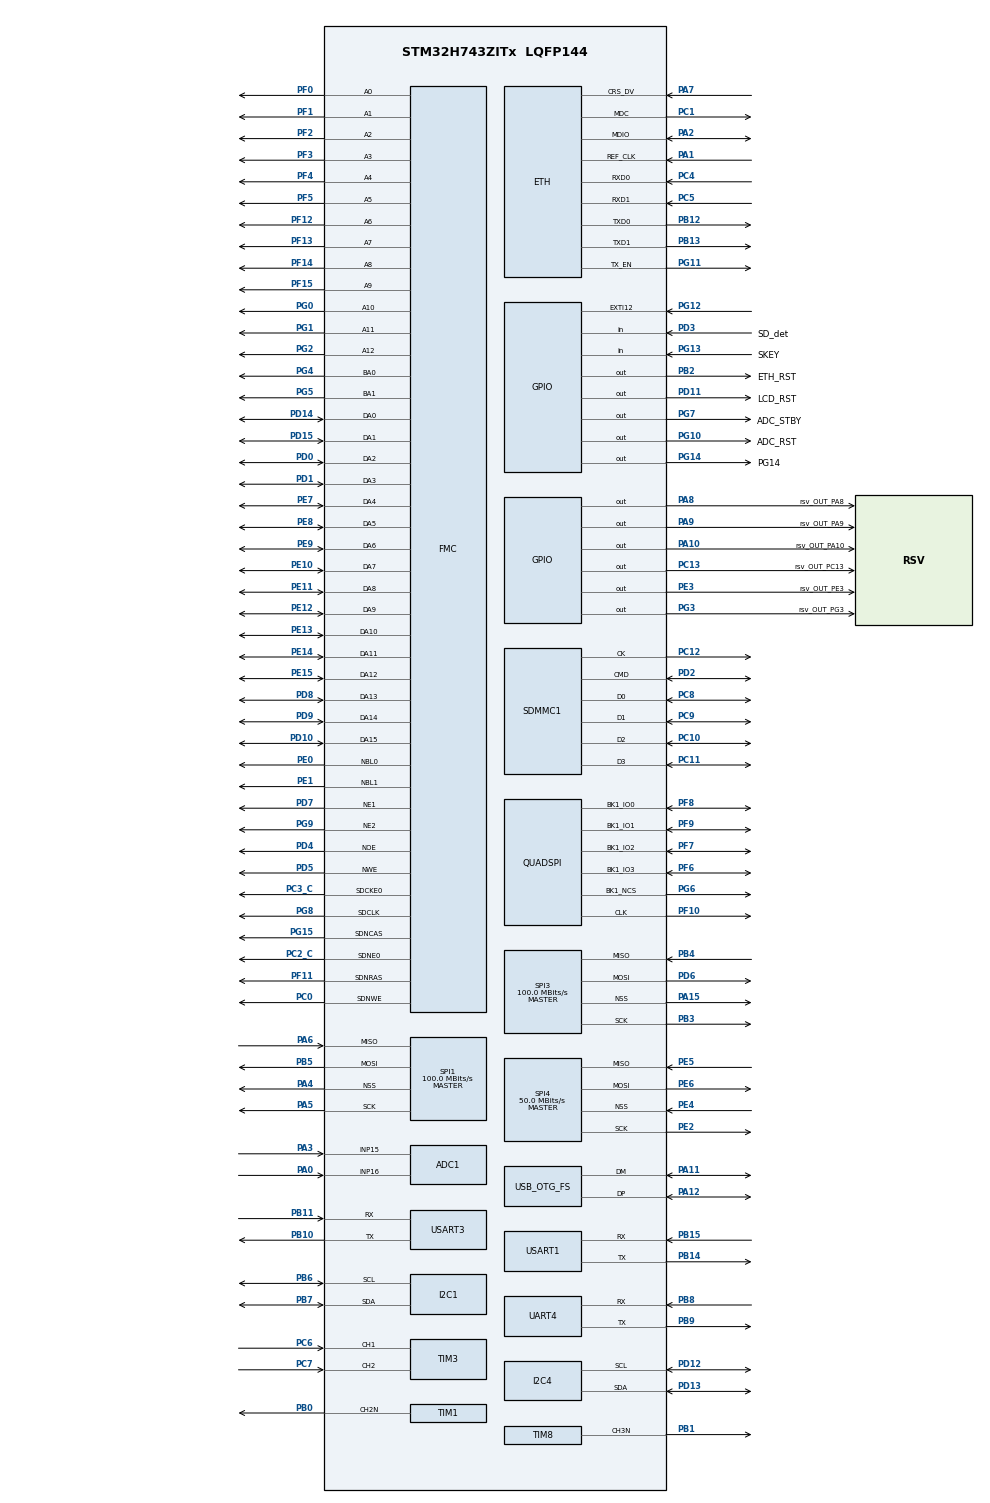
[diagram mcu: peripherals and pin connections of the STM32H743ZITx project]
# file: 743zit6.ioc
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ADC1.Channel-0\#ChannelRegularConversion=ADC_CHANNEL_15
ADC1.NbrOfConversionFlag=1
ADC1.OffsetNumber-0\#ChannelRegularConversion=ADC_OFFSET_NONE
ADC1.OffsetSignedSaturation-0\#ChannelRegularConversion=DISABLE
ADC1.Rank-0\#ChannelRegularConversion=1
ADC1.SamplingTime-0\#ChannelRegularConversion=ADC_SAMPLETIME_1CYCLE_5
ADC1.master=1
CORTEX_M7.AccessPermission-Cortex_Memory_Protection_Unit_Region0_Settings=MPU_REGION_FULL_ACCESS
CORTEX_M7.AccessPermission-Cortex_Memory_Protection_Unit_Region1_Settings=MPU_REGION_FULL_ACCESS
CORTEX_M7.AccessPermission-Cortex_Memory_Protection_Unit_Region2_Settings=MPU_REGION_FULL_ACCESS
CORTEX_M7.AccessPermission-Cortex_Memory_Protection_Unit_Region3_Settings=MPU_REGION_FULL_ACCESS
CORTEX_M7.BaseAddress-Cortex_Memory_Protection_Unit_Region0_Settings=0x30040000
CORTEX_M7.BaseAddress-Cortex_Memory_Protection_Unit_Region1_Settings=0x30044000
CORTEX_M7.BaseAddress-Cortex_Memory_Protection_Unit_Region2_Settings=0x64000000
CORTEX_M7.BaseAddress-Cortex_Memory_Protection_Unit_Region3_Settings=0xC0000000
CORTEX_M7.CPU_DCache=Enabled
CORTEX_M7.CPU_ICache=Enabled
CORTEX_M7.Enable-Cortex_Memory_Protection_Unit_Region0_Settings=MPU_REGION_ENABLE
CORTEX_M7.Enable-Cortex_Memory_Protection_Unit_Region1_Settings=MPU_REGION_ENABLE
CORTEX_M7.Enable-Cortex_Memory_Protection_Unit_Region2_Settings=MPU_REGION_ENABLE
CORTEX_M7.Enable-Cortex_Memory_Protection_Unit_Region3_Settings=MPU_REGION_ENABLE
CORTEX_M7.IsBufferable-Cortex_Memory_Protection_Unit_Region0_Settings=MPU_ACCESS_BUFFERABLE
CORTEX_M7.IsBufferable-Cortex_Memory_Protection_Unit_Region2_Settings=MPU_ACCESS_BUFFERABLE
CORTEX_M7.IsBufferable-Cortex_Memory_Protection_Unit_Region3_Settings=MPU_ACCESS_BUFFERABLE
CORTEX_M7.IsCacheable-Cortex_Memory_Protection_Unit_Region1_Settings=MPU_ACCESS_CACHEABLE
CORTEX_M7.IsCacheable-Cortex_Memory_Protection_Unit_Region3_Settings=MPU_ACCESS_CACHEABLE
CORTEX_M7.MPU_Control=MPU_PRIVILEGED_DEFAULT
CORTEX_M7.Size-Cortex_Memory_Protection_Unit_Region0_Settings=MPU_REGION_SIZE_256B
CORTEX_M7.Size-Cortex_Memory_Protection_Unit_Region1_Settings=MPU_REGION_SIZE_16KB
CORTEX_M7.Size-Cortex_Memory_Protection_Unit_Region2_Settings=MPU_REGION_SIZE_256MB
CORTEX_M7.Size-Cortex_Memory_Protection_Unit_Region3_Settings=MPU_REGION_SIZE_32MB
CORTEX_M7.TypeExtField-Cortex_Memory_Protection_Unit_Region3_Settings=MPU_TEX_LEVEL1
ETH.MediaInterface=HAL_ETH_RMII_MODE
FATFS.BSP.number=1
FATFS0.BSP.STBoard=false
FATFS0.BSP.api=Unknown
FATFS0.BSP.instance=PD3
FATFS0.BSP.ip=GPIO
FATFS0.BSP.mode=Input
FATFS0.BSP.name=Detect_SDIO
FATFS0.BSP.solution=PD3
FMC.AddressSetupTime2=0
FMC.BusTurnAroundDuration2=15
FMC.CASLatency1=FMC_SDRAM_CAS_LATENCY_2
FMC.ColumnBitsNumber1=FMC_SDRAM_COLUMN_BITS_NUM_9
FMC.DataSetupTime2=15
FMC.ExitSelfRefreshDelay1=8
FMC.ExtendedMode2=FMC_EXTENDED_MODE_DISABLE
FMC.LoadToActiveDelay1=2
FMC.RCDDelay1=2
FMC.RPDelay1=2
FMC.RPDelay2=2
FMC.ReadBurst1=FMC_SDRAM_RBURST_ENABLE
FMC.ReadBurst2=FMC_SDRAM_RBURST_ENABLE
FMC.RowCycleDelay1=6
FMC.RowCycleDelay2=6
FMC.SDClockPeriod1=FMC_SDRAM_CLOCK_PERIOD_2
FMC.SDClockPeriod2=FMC_SDRAM_CLOCK_PERIOD_2
FMC.SelfRefreshTime1=6
FMC.WriteFifo1=FMC_WRITE_FIFO_ENABLE
FMC.WriteOperation1=FMC_WRITE_OPERATION_ENABLE
FMC.WriteRecoveryTime1=4
FREERTOS.BinarySemaphores01=EVENT_ADC,Dynamic,NULL,Available;EVENT_FFT,Dynamic,NULL,Available;EVENT_LVGL_REFERSH,Dynamic,NULL,Available;EVENT_LVGL_TASK,Dynamic,NULL,Available
FREERTOS.Tasks01=refersh_lvgl,1,1024,Refersh_LVGL,Default,NULL,Dynamic,NULL,NULL;task_FFT,0,1300,TASK_FFT,Default,NULL,Dynamic,NULL,NULL;task_lvgl,0,1300,TASK_LVGL,Default,NULL,Dynamic,NULL,NULL
FREERTOS.configENABLE_FPU=1
FREERTOS.configTOTAL_HEAP_SIZE=64*1024
FREERTOS.configUSE_MALLOC_FAILED_HOOK=1
FREERTOS.configUSE_MUTEXES=1
I2C1.Timing=0x10C0ECFF
I2C4.Timing=0x10C0ECFF
LWIP.BSP.number=1
LWIP.GATEWAY_ADDRESS=059.067.235.129
LWIP.IP_ADDRESS=059.067.235.208
LWIP.LWIP_DHCP=0
LWIP.LWIP_HTTPD=1
LWIP.LWIP_HTTPD_CGI=1
LWIP.LWIP_HTTPD_SSI=1
LWIP.MEM_SIZE=14336
LWIP.NETMASK_ADDRESS=255.255.255.000
LWIP.Version=v2.1.2_Cube
LWIP0.BSP.STBoard=false
LWIP0.BSP.api=BSP_COMPONENT_DRIVER
LWIP0.BSP.component=LAN8742
LWIP0.BSP.instance=LAN8742
LWIP0.BSP.name=Driver_PHY
LWIP0.BSP.solution=LAN8742
Mcu.Family=STM32H7
Mcu.Name=STM32H743ZITx
Mcu.Package=LQFP144
NVIC.ETH_IRQn=true\:5\:0\:false\:false\:false\:true\:true\:true\:true
NVIC.EXTI15_10_IRQn=true\:5\:0\:false\:false\:true\:true\:true\:true\:true
NVIC.PriorityGroup=NVIC_PRIORITYGROUP_4
NVIC.TIM4_IRQn=true\:15\:0\:false\:false\:true\:false\:false\:true\:true
NVIC.TimeBase=TIM4_IRQn
NVIC.TimeBaseIP=TIM4
PA0.Mode=IN16-Single-Ended
PA0.Signal=ADC1_INP16
PA1.GPIO_Speed=GPIO_SPEED_FREQ_VERY_HIGH
PA1.Mode=RMII
PA1.Signal=ETH_REF_CLK
PA10.GPIO_Label=rsv_OUT_PA10
PA10.Signal=GPIO_Output
PA11.GPIO_Speed=GPIO_SPEED_FREQ_VERY_HIGH
PA11.Mode=Device_Only
PA11.Signal=USB_OTG_FS_DM
PA12.GPIO_Speed=GPIO_SPEED_FREQ_VERY_HIGH
PA12.Mode=Device_Only
PA12.Signal=USB_OTG_FS_DP
PA13\ (JTMS/SWDIO).Mode=Serial_Wire
PA13\ (JTMS/SWDIO).Signal=DEBUG_JTMS-SWDIO
PA14\ (JTCK/SWCLK).Mode=Serial_Wire
PA14\ (JTCK/SWCLK).Signal=DEBUG_JTCK-SWCLK
PA15\ (JTDI).Mode=NSS_Signal_Hard_Output
PA15\ (JTDI).Signal=SPI3_NSS
PA2.GPIO_Speed=GPIO_SPEED_FREQ_VERY_HIGH
PA2.Mode=RMII
PA2.Signal=ETH_MDIO
PA3.Signal=ADCx_INP15
PA4.Mode=NSS_Signal_Hard_Output
PA4.Signal=SPI1_NSS
PA5.Mode=Full_Duplex_Master
PA5.Signal=SPI1_SCK
PA6.Mode=Full_Duplex_Master
PA6.Signal=SPI1_MISO
PA7.GPIO_Speed=GPIO_SPEED_FREQ_VERY_HIGH
PA7.Mode=RMII
PA7.Signal=ETH_CRS_DV
PA8.GPIO_Label=rsv_OUT_PA8
PA8.Signal=GPIO_Output
PA9.GPIO_Label=rsv_OUT_PA9
PA9.Signal=GPIO_Output
PB0.Mode=PWM Generation2 CH2N
PB0.Signal=TIM1_CH2N
PB1.Mode=PWM Generation3 CH3N
PB1.Signal=TIM8_CH3N
PB10.Mode=Asynchronous
PB10.Signal=USART3_TX
PB11.Mode=Asynchronous
PB11.Signal=USART3_RX
PB12.GPIO_Speed=GPIO_SPEED_FREQ_VERY_HIGH
PB12.Mode=RMII
PB12.Signal=ETH_TXD0
PB13.GPIO_Speed=GPIO_SPEED_FREQ_VERY_HIGH
PB13.Mode=RMII
PB13.Signal=ETH_TXD1
PB14.Mode=Asynchronous
PB14.Signal=USART1_TX
PB15.Mode=Asynchronous
PB15.Signal=USART1_RX
PB2.GPIO_Label=ETH_RST
PB2.Signal=GPIO_Output
PB3\ (JTDO/TRACESWO).Mode=Full_Duplex_Master
PB3\ (JTDO/TRACESWO).Signal=SPI3_SCK
PB4\ (NJTRST).Mode=Full_Duplex_Master
PB4\ (NJTRST).Signal=SPI3_MISO
PB5.Mode=Full_Duplex_Master
PB5.Signal=SPI1_MOSI
PB6.Mode=I2C
PB6.Signal=I2C1_SCL
PB7.Mode=I2C
PB7.Signal=I2C1_SDA
PB8.Mode=Asynchronous
PB8.Signal=UART4_RX
PB9.Mode=Asynchronous
PB9.Signal=UART4_TX
PC0.Signal=FMC_SDNWE
PC1.GPIO_Speed=GPIO_SPEED_FREQ_VERY_HIGH
PC1.Mode=RMII
PC1.Signal=ETH_MDC
PC10.Mode=SD_4_bits_Wide_bus
PC10.Signal=SDMMC1_D2
PC11.Mode=SD_4_bits_Wide_bus
PC11.Signal=SDMMC1_D3
PC12.Mode=SD_4_bits_Wide_bus
PC12.Signal=SDMMC1_CK
PC13.GPIO_Label=rsv_OUT_PC13
PC13.Signal=GPIO_Output
PC14-OSC32_IN\ (OSC32_IN).Mode=LSE-External-Oscillator
PC14-OSC32_IN\ (OSC32_IN).Signal=RCC_OSC32_IN
PC15-OSC32_OUT\ (OSC32_OUT).Mode=LSE-External-Oscillator
PC15-OSC32_OUT\ (OSC32_OUT).Signal=RCC_OSC32_OUT
PC2_C.Mode=SdramChipSelect1_1
PC2_C.Signal=FMC_SDNE0
PC3_C.Mode=SdramChipSelect1_1
PC3_C.Signal=FMC_SDCKE0
PC4.GPIO_Speed=GPIO_SPEED_FREQ_VERY_HIGH
PC4.Mode=RMII
PC4.Signal=ETH_RXD0
PC5.GPIO_Speed=GPIO_SPEED_FREQ_VERY_HIGH
PC5.Mode=RMII
PC5.Signal=ETH_RXD1
PC6.Signal=S_TIM3_CH1
PC7.Signal=S_TIM3_CH2
PC8.Mode=SD_4_bits_Wide_bus
PC8.Signal=SDMMC1_D0
PC9.Mode=SD_4_bits_Wide_bus
PC9.Signal=SDMMC1_D1
PD0.Signal=FMC_D2_DA2
PD1.Signal=FMC_D3_DA3
PD10.Signal=FMC_D15_DA15
PD11.GPIO_Label=LCD_RST
PD11.Signal=GPIO_Output
PD12.Mode=I2C
PD12.Signal=I2C4_SCL
PD13.Mode=I2C
PD13.Signal=I2C4_SDA
PD14.Signal=FMC_D0_DA0
PD15.Signal=FMC_D1_DA1
PD2.Mode=SD_4_bits_Wide_bus
PD2.Signal=SDMMC1_CMD
PD3.GPIO_Label=SD_det
PD3.Signal=GPIO_Input
PD4.Signal=FMC_NOE
PD5.Signal=FMC_NWE
PD6.Mode=Full_Duplex_Master
PD6.Signal=SPI3_MOSI
PD7.Mode=NorPsramChipSelect1_1
PD7.Signal=FMC_NE1
PD8.Signal=FMC_D13_DA13
PD9.Signal=FMC_D14_DA14
PE0.Signal=FMC_NBL0
PE1.Signal=FMC_NBL1
PE10.Signal=FMC_D7_DA7
PE11.Signal=FMC_D8_DA8
PE12.Signal=FMC_D9_DA9
PE13.Signal=FMC_D10_DA10
PE14.Signal=FMC_D11_DA11
PE15.Signal=FMC_D12_DA12
PE2.Mode=Full_Duplex_Master
PE2.Signal=SPI4_SCK
PE3.GPIO_Label=rsv_OUT_PE3
PE3.Signal=GPIO_Output
PE4.Mode=NSS_Signal_Hard_Input
PE4.Signal=SPI4_NSS
PE5.Mode=Full_Duplex_Master
PE5.Signal=SPI4_MISO
PE6.Mode=Full_Duplex_Master
PE6.Signal=SPI4_MOSI
PE7.Signal=FMC_D4_DA4
PE8.Signal=FMC_D5_DA5
PE9.Signal=FMC_D6_DA6
PF0.Signal=FMC_A0
PF1.Signal=FMC_A1
PF10.Mode=Single Bank 1
PF10.Signal=QUADSPI_CLK
PF11.Signal=FMC_SDNRAS
PF12.Signal=FMC_A6
PF13.Signal=FMC_A7
PF14.Signal=FMC_A8
PF15.Signal=FMC_A9
PF2.Signal=FMC_A2
PF3.Signal=FMC_A3
PF4.Signal=FMC_A4
PF5.Signal=FMC_A5
PF6.Mode=Single Bank 1
PF6.Signal=QUADSPI_BK1_IO3
PF7.Mode=Single Bank 1
PF7.Signal=QUADSPI_BK1_IO2
PF8.Mode=Single Bank 1
PF8.Signal=QUADSPI_BK1_IO0
PF9.Mode=Single Bank 1
PF9.Signal=QUADSPI_BK1_IO1
PG0.Signal=FMC_A10
PG1.Signal=FMC_A11
PG10.GPIO_Label=ADC_RST
PG10.Signal=GPIO_Output
PG11.GPIO_Speed=GPIO_SPEED_FREQ_VERY_HIGH
PG11.Mode=RMII
PG11.Signal=ETH_TX_EN
PG12.Signal=GPXTI12
PG13.GPIO_Label=SKEY
PG13.Signal=GPIO_Input
PG14.GPIO_Label=PG14
PG14.Signal=GPIO_Output
PG15.Signal=FMC_SDNCAS
PG2.Signal=FMC_A12
PG3.GPIO_Label=rsv_OUT_PG3
PG3.Signal=GPIO_Output
PG4.Signal=FMC_A14_BA0
PG5.Signal=FMC_A15_BA1
PG6.Mode=Single Bank 1
PG6.Signal=QUADSPI_BK1_NCS
PG7.GPIO_Label=ADC_STBY
PG7.Signal=GPIO_Output
PG8.Signal=FMC_SDCLK
PG9.Mode=NorPsramChipSelect2_2
PG9.Signal=FMC_NE2
PH0-OSC_IN\ (PH0).Mode=HSE-External-Oscillator
PH0-OSC_IN\ (PH0).Signal=RCC_OSC_IN
PH1-OSC_OUT\ (PH1).Mode=HSE-External-Oscillator
PH1-OSC_OUT\ (PH1).Signal=RCC_OSC_OUT
ProjectManager.HeapSize=0x200
ProjectManager.StackSize=0x400
ProjectManager.TargetToolchain=Makefile
RCC.ADCFreq_Value=75000000
RCC.APB1Freq_Value=100000000
RCC.APB2Freq_Value=100000000
RCC.APB3Freq_Value=100000000
RCC.APB4Freq_Value=100000000
RCC.CortexFreq_Value=400000000
RCC.D1PPRE=RCC_APB3_DIV2
RCC.D2PPRE1=RCC_APB1_DIV2
RCC.D2PPRE2=RCC_APB2_DIV2
RCC.D3PPRE=RCC_APB4_DIV2
RCC.DIVM1=1
RCC.DIVM2=1
RCC.DIVN1=97
RCC.DIVN2=18
RCC.DIVQ1=4
RCC.HCLKFreq_Value=200000000
RCC.HPRE=RCC_HCLK_DIV2
RCC.HSE_VALUE=8192000
RCC.PLL2FRACN=2544
RCC.PLL2_VCI_Range-AdvancedSettings=RCC_PLL2VCIRANGE_0
RCC.PLL3_VCO_SEL-AdvancedSettings=RCC_PLL3VCOWIDE
RCC.PLLFRACN=5376
RCC.PLLSourceVirtual=RCC_PLLSOURCE_HSE
RCC.PWR_Regulator_Voltage_Scale=PWR_REGULATOR_VOLTAGE_SCALE0
RCC.RTCClockSelection=RCC_RTCCLKSOURCE_LSE
RCC.SYSCLKFreq_VALUE=400000000
RCC.SYSCLKSource=RCC_SYSCLKSOURCE_PLLCLK
RCC.USBCLockSelection=RCC_USBCLKSOURCE_HSI48
RCC.USBFreq_Value=48000000
RTC.Format=RTC_FORMAT_BIN
SH.ADCx_INP15.0=ADC1_INP15,IN15-Single-Ended
SH.FMC_A0.0=FMC_A0,13b-sda1
SH.FMC_A1.0=FMC_A1,13b-sda1
SH.FMC_A10.0=FMC_A10,13b-sda1
SH.FMC_A11.0=FMC_A11,13b-sda1
SH.FMC_A12.0=FMC_A12,13b-sda1
SH.FMC_A14_BA0.0=FMC_BA0,FourSdramBanks1
SH.FMC_A15_BA1.0=FMC_BA1,FourSdramBanks1
SH.FMC_A2.0=FMC_A2,13b-sda1
SH.FMC_A3.0=FMC_A3,13b-sda1
SH.FMC_A4.0=FMC_A4,13b-sda1
SH.FMC_A5.0=FMC_A5,13b-sda1
SH.FMC_A6.0=FMC_A6,A6_2
SH.FMC_A6.1=FMC_A6,13b-sda1
SH.FMC_A7.0=FMC_A7,13b-sda1
SH.FMC_A8.0=FMC_A8,13b-sda1
SH.FMC_A9.0=FMC_A9,13b-sda1
SH.FMC_D0_DA0.0=FMC_DA0,16b-da1
SH.FMC_D0_DA0.1=FMC_D0,16b-d2
SH.FMC_D0_DA0.2=FMC_D0,sd-16b-d1
SH.FMC_D10_DA10.0=FMC_DA10,16b-da1
SH.FMC_D10_DA10.1=FMC_D10,16b-d2
SH.FMC_D10_DA10.2=FMC_D10,sd-16b-d1
SH.FMC_D11_DA11.0=FMC_DA11,16b-da1
SH.FMC_D11_DA11.1=FMC_D11,16b-d2
SH.FMC_D11_DA11.2=FMC_D11,sd-16b-d1
SH.FMC_D12_DA12.0=FMC_DA12,16b-da1
SH.FMC_D12_DA12.1=FMC_D12,16b-d2
SH.FMC_D12_DA12.2=FMC_D12,sd-16b-d1
SH.FMC_D13_DA13.0=FMC_DA13,16b-da1
SH.FMC_D13_DA13.1=FMC_D13,16b-d2
SH.FMC_D13_DA13.2=FMC_D13,sd-16b-d1
SH.FMC_D14_DA14.0=FMC_DA14,16b-da1
SH.FMC_D14_DA14.1=FMC_D14,16b-d2
SH.FMC_D14_DA14.2=FMC_D14,sd-16b-d1
SH.FMC_D15_DA15.0=FMC_DA15,16b-da1
SH.FMC_D15_DA15.1=FMC_D15,16b-d2
SH.FMC_D15_DA15.2=FMC_D15,sd-16b-d1
SH.FMC_D1_DA1.0=FMC_DA1,16b-da1
SH.FMC_D1_DA1.1=FMC_D1,16b-d2
SH.FMC_D1_DA1.2=FMC_D1,sd-16b-d1
SH.FMC_D2_DA2.0=FMC_DA2,16b-da1
SH.FMC_D2_DA2.1=FMC_D2,16b-d2
SH.FMC_D2_DA2.2=FMC_D2,sd-16b-d1
SH.FMC_D3_DA3.0=FMC_DA3,16b-da1
SH.FMC_D3_DA3.1=FMC_D3,16b-d2
SH.FMC_D3_DA3.2=FMC_D3,sd-16b-d1
SH.FMC_D4_DA4.0=FMC_DA4,16b-da1
SH.FMC_D4_DA4.1=FMC_D4,16b-d2
SH.FMC_D4_DA4.2=FMC_D4,sd-16b-d1
SH.FMC_D5_DA5.0=FMC_DA5,16b-da1
SH.FMC_D5_DA5.1=FMC_D5,16b-d2
SH.FMC_D5_DA5.2=FMC_D5,sd-16b-d1
SH.FMC_D6_DA6.0=FMC_DA6,16b-da1
SH.FMC_D6_DA6.1=FMC_D6,16b-d2
SH.FMC_D6_DA6.2=FMC_D6,sd-16b-d1
SH.FMC_D7_DA7.0=FMC_DA7,16b-da1
SH.FMC_D7_DA7.1=FMC_D7,16b-d2
SH.FMC_D7_DA7.2=FMC_D7,sd-16b-d1
SH.FMC_D8_DA8.0=FMC_DA8,16b-da1
SH.FMC_D8_DA8.1=FMC_D8,16b-d2
SH.FMC_D8_DA8.2=FMC_D8,sd-16b-d1
SH.FMC_D9_DA9.0=FMC_DA9,16b-da1
SH.FMC_D9_DA9.1=FMC_D9,16b-d2
SH.FMC_D9_DA9.2=FMC_D9,sd-16b-d1
SH.FMC_NBL0.0=FMC_NBL0,Sd2ByteEnable1
SH.FMC_NBL1.0=FMC_NBL1,Sd2ByteEnable1
SH.FMC_NOE.0=FMC_NOE,MuxedPsram1
SH.FMC_NOE.1=FMC_NOE,Lcd2
SH.FMC_NWE.0=FMC_NWE,MuxedPsram1
SH.FMC_NWE.1=FMC_NWE,Lcd2
SH.FMC_SDCLK.0=FMC_SDCLK,13b-sda1
SH.FMC_SDNCAS.0=FMC_SDNCAS,13b-sda1
SH.FMC_SDNRAS.0=FMC_SDNRAS,13b-sda1
SH.FMC_SDNWE.0=FMC_SDNWE,13b-sda1
SH.S_TIM3_CH1.0=TIM3_CH1,Encoder_Interface
SH.S_TIM3_CH2.0=TIM3_CH2,Encoder_Interface
SPI1.CalculateBaudRate=100.0 MBits/s
SPI1.Direction=SPI_DIRECTION_2LINES
SPI1.Mode=SPI_MODE_MASTER
SPI1.VirtualNSS=VM_NSSHARD
SPI1.VirtualType=VM_MASTER
SPI3.CalculateBaudRate=100.0 MBits/s
SPI3.Direction=SPI_DIRECTION_2LINES
SPI3.Mode=SPI_MODE_MASTER
SPI3.VirtualNSS=VM_NSSHARD
SPI3.VirtualType=VM_MASTER
SPI4.CalculateBaudRate=50.0 MBits/s
SPI4.Direction=SPI_DIRECTION_2LINES
SPI4.Mode=SPI_MODE_MASTER
SPI4.VirtualNSS=VM_NSSHARD
SPI4.VirtualType=VM_MASTER
TIM1.AutoReloadPreload=TIM_AUTORELOAD_PRELOAD_ENABLE
TIM1.Channel-PWM\ Generation2\ CH2N=TIM_CHANNEL_2
TIM1.Period=1000
TIM1.Prescaler=240-1
TIM1.Pulse-PWM\ Generation2\ CH2N=500
TIM8.AutoReloadPreload=TIM_AUTORELOAD_PRELOAD_ENABLE
TIM8.Channel-PWM\ Generation3\ CH3N=TIM_CHANNEL_3
TIM8.Period=25-1
TIM8.Prescaler=625-1
TIM8.Pulse-PWM\ Generation3\ CH3N=10
USART1.VirtualMode-Asynchronous=VM_ASYNC
USART3.VirtualMode-Asynchronous=VM_ASYNC
USB_OTG_FS.VirtualMode=Device_Only
VP_FATFS_VS_SDIO.Mode=SDIO
VP_FREERTOS_VS_CMSIS_V1.Mode=CMSIS_V1
VP_LWIP_VS_Enabled.Mode=Enabled
VP_RTC_VS_RTC_Activate.Mode=RTC_Enabled
VP_RTC_VS_RTC_Calendar.Mode=RTC_Calendar
VP_SYS_VS_tim4.Mode=TIM4
VP_TIM1_VS_ClockSourceINT.Mode=Internal
VP_TIM8_VS_ClockSourceINT.Mode=Internal
board=custom

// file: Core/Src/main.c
/* USER CODE BEGIN Header */
/**
  ******************************************************************************
  * @file           : main.c
  * @brief          : Main program body
  ******************************************************************************
  * @attention
  *
  * <h2><center>&copy; Copyright (c) 2024 STMicroelectronics.
  * All rights reserved.</center></h2>
  *
  * This software component is licensed by ST under BSD 3-Clause license,
  * the "License"; You may not use this file except in compliance with the
  * License. You may obtain a copy of the License at:
  *                        opensource.org/licenses/BSD-3-Clause
  *
  ******************************************************************************
  */
/* USER CODE END Header */
#include "main.h"
#include "cmsis_os.h"
#include "adc.h"
#include "fatfs.h"
#include "i2c.h"
#include "lwip.h"
#include "quadspi.h"
#include "rtc.h"
#include "sdmmc.h"
#include "spi.h"
#include "tim.h"
#include "usart.h"
#include "usb_otg.h"
#include "gpio.h"
#include "fmc.h"

/* USER CODE BEGIN Includes */
#include "sdmmc.h"
#include "ad7606.h"
#include "lcd.h"
#include "lv_port_indev.h"
#include "lvgl.h"
#include "lv_port_fs.h"
#include "lv_port_disp.h"
#include "fatfs.h"
#include "gui_guider.h"
#include "events_init.h"
#include "sdcard_test.h"
#include "arm_math.h"
#include "dsp_fft.h"
#include "lv_snapshot.h"
#include "lv_bmp.h"
// #include "task_page1.h"
#include "sdram.h"
/* USER CODE END Includes */

/* USER CODE BEGIN PTD */
lv_ui guider_ui;

/* USER CODE END PTD */

/* USER CODE BEGIN PV */
AD7606Dev ad7606dev;
short adcResult;
short adcBuf[testCHs];
uint16_t cnt=0;
uint16_t MyRTC_Time[] = {0, 0, 0, 0, 0, 0};
/* USER CODE END PV */

void SystemClock_Config(void);
static void MPU_Config(void);
void MX_FREERTOS_Init(void);

int main(void)
{

  /* MPU Configuration--------------------------------------------------------*/
  MPU_Config();

  /* Enable I-Cache---------------------------------------------------------*/
  SCB_EnableICache();

  /* Enable D-Cache---------------------------------------------------------*/
  SCB_EnableDCache();

  /* MCU Configuration--------------------------------------------------------*/

  /* Reset of all peripherals, Initializes the Flash interface and the Systick. */
  HAL_Init();

  /* Configure the system clock */
  SystemClock_Config();

  /* Initialize all configured peripherals */
  MX_GPIO_Init();
  MX_RTC_Init();
  MX_TIM1_Init();
  MX_ADC1_Init();
  MX_USB_OTG_FS_PCD_Init();
  MX_TIM3_Init();
  MX_FMC_Init();
  MX_I2C1_Init();
  MX_I2C4_Init();
  MX_QUADSPI_Init();
  MX_SDMMC1_SD_Init();
  MX_SPI1_Init();
  MX_SPI3_Init();
  MX_SPI4_Init();
  MX_TIM8_Init();
  MX_UART4_Init();
  MX_USART1_UART_Init();
  MX_USART3_UART_Init();
  MX_FATFS_Init();
  /* USER CODE BEGIN 2 */

 // HAL_NVIC_DisableIRQ(EXTI15_10_IRQn);
  // HAL_FMC_MspInit();

  lv_init();

  lv_port_disp_init();
  lv_port_indev_init();
  HAL_Delay(10);
  setup_ui(&guider_ui);
  HAL_SD_MspInit(&hsd1);

  HAL_TIM_Base_Start_IT(&htim1);
  ad7606ini(&ad7606dev);
  MX_FATFS_Init();
  //MyRTC_ReadTime();
  HAL_Delay(100);
  FatFs_Check();
  lv_port_fs_init();
  events_init(&guider_ui);

  // HAL_TIMEx_PWMN_Start(&htim1,TIM_CHANNEL_2);
  // ad7606ini(&ad7606dev);
  // HAL_TIMEx_PWMN_Start(&htim8,TIM_CHANNEL_3);

  /* USER CODE END 2 */

  /* Call init function for freertos objects (in freertos.c) */
  MX_FREERTOS_Init();
  /* Start scheduler */
  osKernelStart();

  /* We should never get here as control is now taken by the scheduler */
  /* Infinite loop */
  while (1)
  {

  }
}

void SystemClock_Config(void)
{
  RCC_OscInitTypeDef RCC_OscInitStruct = {0};
  RCC_ClkInitTypeDef RCC_ClkInitStruct = {0};

  /** Supply configuration update enable
  */
  HAL_PWREx_ConfigSupply(PWR_LDO_SUPPLY);
  /** Configure the main internal regulator output voltage
  */
  __HAL_PWR_VOLTAGESCALING_CONFIG(PWR_REGULATOR_VOLTAGE_SCALE0);

  while(!__HAL_PWR_GET_FLAG(PWR_FLAG_VOSRDY)) {}
  /** Configure LSE Drive Capability
  */
  HAL_PWR_EnableBkUpAccess();
  __HAL_RCC_LSEDRIVE_CONFIG(RCC_LSEDRIVE_LOW);
  /** Macro to configure the PLL clock source
  */
  __HAL_RCC_PLL_PLLSOURCE_CONFIG(RCC_PLLSOURCE_HSE);
  /** Initializes the RCC Oscillators according to the specified parameters
  * in the RCC_OscInitTypeDef structure.
  */
  RCC_OscInitStruct.OscillatorType = RCC_OSCILLATORTYPE_HSI48|RCC_OSCILLATORTYPE_HSE
                              |RCC_OSCILLATORTYPE_LSE;
  RCC_OscInitStruct.HSEState = RCC_HSE_ON;
  RCC_OscInitStruct.LSEState = RCC_LSE_ON;
  RCC_OscInitStruct.HSI48State = RCC_HSI48_ON;
  RCC_OscInitStruct.PLL.PLLState = RCC_PLL_ON;
  RCC_OscInitStruct.PLL.PLLSource = RCC_PLLSOURCE_HSE;
  RCC_OscInitStruct.PLL.PLLM = 1;
  RCC_OscInitStruct.PLL.PLLN = 97;
  RCC_OscInitStruct.PLL.PLLP = 2;
  RCC_OscInitStruct.PLL.PLLQ = 4;
  RCC_OscInitStruct.PLL.PLLR = 2;
  RCC_OscInitStruct.PLL.PLLRGE = RCC_PLL1VCIRANGE_3;
  RCC_OscInitStruct.PLL.PLLVCOSEL = RCC_PLL1VCOWIDE;
  RCC_OscInitStruct.PLL.PLLFRACN = 5376;
  if (HAL_RCC_OscConfig(&RCC_OscInitStruct) != HAL_OK)
  {
    Error_Handler();
  }
  /** Initializes the CPU, AHB and APB buses clocks
  */
  RCC_ClkInitStruct.ClockType = RCC_CLOCKTYPE_HCLK|RCC_CLOCKTYPE_SYSCLK
                              |RCC_CLOCKTYPE_PCLK1|RCC_CLOCKTYPE_PCLK2
                              |RCC_CLOCKTYPE_D3PCLK1|RCC_CLOCKTYPE_D1PCLK1;
  RCC_ClkInitStruct.SYSCLKSource = RCC_SYSCLKSOURCE_PLLCLK;
  RCC_ClkInitStruct.SYSCLKDivider = RCC_SYSCLK_DIV1;
  RCC_ClkInitStruct.AHBCLKDivider = RCC_HCLK_DIV2;
  RCC_ClkInitStruct.APB3CLKDivider = RCC_APB3_DIV2;
  RCC_ClkInitStruct.APB1CLKDivider = RCC_APB1_DIV2;
  RCC_ClkInitStruct.APB2CLKDivider = RCC_APB2_DIV2;
  RCC_ClkInitStruct.APB4CLKDivider = RCC_APB4_DIV2;

  if (HAL_RCC_ClockConfig(&RCC_ClkInitStruct, FLASH_LATENCY_2) != HAL_OK)
  {
    Error_Handler();
  }
}

/* MPU Configuration */

void MPU_Config(void)
{
  MPU_Region_InitTypeDef MPU_InitStruct = {0};

  /* Disables the MPU */
  HAL_MPU_Disable();
  /** Initializes and configures the Region and the memory to be protected
  */
  MPU_InitStruct.Enable = MPU_REGION_ENABLE;
  MPU_InitStruct.Number = MPU_REGION_NUMBER0;
  MPU_InitStruct.BaseAddress = 0x30040000;
  MPU_InitStruct.Size = MPU_REGION_SIZE_256B;
  MPU_InitStruct.SubRegionDisable = 0x0;
  MPU_InitStruct.TypeExtField = MPU_TEX_LEVEL0;
  MPU_InitStruct.AccessPermission = MPU_REGION_FULL_ACCESS;
  MPU_InitStruct.DisableExec = MPU_INSTRUCTION_ACCESS_ENABLE;
  MPU_InitStruct.IsShareable = MPU_ACCESS_NOT_SHAREABLE;
  MPU_InitStruct.IsCacheable = MPU_ACCESS_NOT_CACHEABLE;
  MPU_InitStruct.IsBufferable = MPU_ACCESS_BUFFERABLE;

  HAL_MPU_ConfigRegion(&MPU_InitStruct);
  /** Initializes and configures the Region and the memory to be protected
  */
  MPU_InitStruct.Number = MPU_REGION_NUMBER1;
  MPU_InitStruct.BaseAddress = 0x30044000;
  MPU_InitStruct.Size = MPU_REGION_SIZE_16KB;
  MPU_InitStruct.IsCacheable = MPU_ACCESS_CACHEABLE;
  MPU_InitStruct.IsBufferable = MPU_ACCESS_NOT_BUFFERABLE;

  HAL_MPU_ConfigRegion(&MPU_InitStruct);
  /** Initializes and configures the Region and the memory to be protected
  */
  MPU_InitStruct.Number = MPU_REGION_NUMBER2;
  MPU_InitStruct.BaseAddress = 0x64000000;
  MPU_InitStruct.Size = MPU_REGION_SIZE_256MB;
  MPU_InitStruct.IsCacheable = MPU_ACCESS_NOT_CACHEABLE;
  MPU_InitStruct.IsBufferable = MPU_ACCESS_BUFFERABLE;

  HAL_MPU_ConfigRegion(&MPU_InitStruct);
  /** Initializes and configures the Region and the memory to be protected
  */
  MPU_InitStruct.Number = MPU_REGION_NUMBER3;
  MPU_InitStruct.BaseAddress = 0xC0000000;
  MPU_InitStruct.Size = MPU_REGION_SIZE_32MB;
  MPU_InitStruct.TypeExtField = MPU_TEX_LEVEL1;
  MPU_InitStruct.IsCacheable = MPU_ACCESS_CACHEABLE;

  HAL_MPU_ConfigRegion(&MPU_InitStruct);
  /* Enables the MPU */
  HAL_MPU_Enable(MPU_PRIVILEGED_DEFAULT);

}

void HAL_TIM_PeriodElapsedCallback(TIM_HandleTypeDef *htim)
{
  /* USER CODE BEGIN Callback 0 */
  static uint16_t temp = 0;
  static uint16_t counter = 0;

  /* USER CODE END Callback 0 */
  if (htim->Instance == TIM4) {
    HAL_IncTick();
  }
  /* USER CODE BEGIN Callback 1 */
  if (htim->Instance == TIM4)
  {
    temp++;
    counter++;
    if (temp == 5)
    {
      lv_tick_inc(5);
      temp = 0;
    }
  }

  /* USER CODE END Callback 1 */
}

void Error_Handler(void)
{
  __disable_irq();
  while (1)
  {
  }
}

/************************ (C) COPYRIGHT STMicroelectronics *****END OF FILE****/

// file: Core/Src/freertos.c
/* USER CODE BEGIN Header */
/**
 ******************************************************************************
 * File Name          : freertos.c
 * Description        : Code for freertos applications
 ******************************************************************************
 * @attention
 *
 * <h2><center>&copy; Copyright (c) 2024 STMicroelectronics.
 * All rights reserved.</center></h2>
 *
 * This software component is licensed by ST under Ultimate Liberty license
 * SLA0044, the "License"; You may not use this file except in compliance with
 * the License. You may obtain a copy of the License at:
 *                             www.st.com/SLA0044
 *
 ******************************************************************************
 */
/* USER CODE END Header */

#include "FreeRTOS.h"
#include "task.h"
#include "main.h"
#include "cmsis_os.h"

/* USER CODE BEGIN Includes */
#include "lwip/apps/httpd.h"
#include "ad7606.h"
#include "lcd.h"
#include "gui_guider.h"
#include "arm_math.h"
#include "tim.h"
#include "dsp_fft.h"
#include "lvgl.h"
#include "lv_chart.h"
#include "task.h"
#include "task_page1.h"
#include "gpio.h"
#include "sdmmc.h"
#include "events_init.h"
/* USER CODE END Includes */

/* USER CODE BEGIN PTD */
ALIGN_32BYTES(FFT fft_1V)
__attribute__((section(".SDRAM")));

ALIGN_32BYTES(FFT fft_2V)
__attribute__((section(".SDRAM")));
ALIGN_32BYTES(FFT fft_3V)
__attribute__((section(".SDRAM")));
ALIGN_32BYTES(FFT fft_NV)
__attribute__((section(".SDRAM")));

ALIGN_32BYTES(FFT fft_1I)
__attribute__((section(".SDRAM")));
ALIGN_32BYTES(FFT fft_2I)
__attribute__((section(".SDRAM")));
ALIGN_32BYTES(FFT fft_3I)
__attribute__((section(".SDRAM")));
ALIGN_32BYTES(FFT fft_NI)
__attribute__((section(".SDRAM")));

ALIGN_32BYTES(phase P1)
__attribute__((section(".SDRAM")));
ALIGN_32BYTES(phase P2)
__attribute__((section(".SDRAM")));
ALIGN_32BYTES(phase P3)
__attribute__((section(".SDRAM")));
ALIGN_32BYTES(phase PN)
__attribute__((section(".SDRAM")));

ALIGN_32BYTES(Voltage_three Voltage)
__attribute__((section(".SDRAM")));

lv_chart_series_t *ser1;
lv_chart_series_t *ser2;
lv_chart_series_t *ser3;
lv_chart_series_t *serN;

lv_chart_series_t *ser1_I;
lv_chart_series_t *ser2_I;
lv_chart_series_t *ser3_I;
lv_chart_series_t *serN_I;
extern uint8_t V_I_flag;
extern uint8_t L1_flag;
extern uint8_t L2_flag;
extern uint8_t L3_flag;
extern uint8_t LN_flag;
extern uint8_t L1_I_flag;
extern uint8_t L2_I_flag;
extern uint8_t L3_I_flag;
extern uint8_t LN_I_flag;
extern AD7606Dev ad7606dev;
extern SD_HandleTypeDef hsd1;
/* USER CODE END PTD */

osThreadId refersh_lvglHandle;
osThreadId task_FFTHandle;
osThreadId task_lvglHandle;
osSemaphoreId EVENT_ADCHandle;
osSemaphoreId EVENT_FFTHandle;
osSemaphoreId EVENT_LVGL_REFERSHHandle;
osSemaphoreId EVENT_LVGL_TASKHandle;

void Refersh_LVGL(void const *argument);
void TASK_FFT(void const *argument);
void TASK_LVGL(void const *argument);
void init_form_stop();
extern void MX_LWIP_Init(void);
void MX_FREERTOS_Init(void); /* (MISRA C 2004 rule 8.1) */

/* GetIdleTaskMemory prototype (linked to static allocation support) */
void vApplicationGetIdleTaskMemory(StaticTask_t **ppxIdleTaskTCBBuffer, StackType_t **ppxIdleTaskStackBuffer, uint32_t *pulIdleTaskStackSize);

/* Hook prototypes */
void vApplicationMallocFailedHook(void);

/* USER CODE BEGIN 5 */
void vApplicationMallocFailedHook(void)
{
  /* vApplicationMallocFailedHook() will only be called if
  configUSE_MALLOC_FAILED_HOOK is set to 1 in FreeRTOSConfig.h. It is a hook
  function that will get called if a call to pvPortMalloc() fails.
  pvPortMalloc() is called internally by the kernel whenever a task, queue,
  timer or semaphore is created. It is also called by various parts of the
  demo application. If heap_1.c or heap_2.c are used, then the size of the
  heap available to pvPortMalloc() is defined by configTOTAL_HEAP_SIZE in
  FreeRTOSConfig.h, and the xPortGetFreeHeapSize() API function can be used
  to query the size of free heap space that remains (although it does not
  provide information on how the remaining heap might be fragmented). */
  printf("malloc fail\r\n");
  while (1)
  {

    HAL_GPIO_TogglePin(PG14_GPIO_Port, PG14_Pin);
    osDelay(200);
  }
}
/* USER CODE END 5 */

/* USER CODE BEGIN GET_IDLE_TASK_MEMORY */
static StaticTask_t xIdleTaskTCBBuffer;
static StackType_t xIdleStack[configMINIMAL_STACK_SIZE];

void vApplicationGetIdleTaskMemory(StaticTask_t **ppxIdleTaskTCBBuffer, StackType_t **ppxIdleTaskStackBuffer, uint32_t *pulIdleTaskStackSize)
{
  *ppxIdleTaskTCBBuffer = &xIdleTaskTCBBuffer;
  *ppxIdleTaskStackBuffer = &xIdleStack[0];
  *pulIdleTaskStackSize = configMINIMAL_STACK_SIZE;
  /* place for user code */
}
/* USER CODE END GET_IDLE_TASK_MEMORY */

void MX_FREERTOS_Init(void)
{

  /* Create the semaphores(s) */
  /* definition and creation of EVENT_ADC */
  osSemaphoreDef(EVENT_ADC);
  EVENT_ADCHandle = osSemaphoreCreate(osSemaphore(EVENT_ADC), 1);

  /* definition and creation of EVENT_FFT */
  osSemaphoreDef(EVENT_FFT);
  EVENT_FFTHandle = osSemaphoreCreate(osSemaphore(EVENT_FFT), 1);

  /* definition and creation of EVENT_LVGL_REFERSH */
  osSemaphoreDef(EVENT_LVGL_REFERSH);
  EVENT_LVGL_REFERSHHandle = osSemaphoreCreate(osSemaphore(EVENT_LVGL_REFERSH), 1);

  /* definition and creation of EVENT_LVGL_TASK */
  osSemaphoreDef(EVENT_LVGL_TASK);
  EVENT_LVGL_TASKHandle = osSemaphoreCreate(osSemaphore(EVENT_LVGL_TASK), 1);

  /* Create the thread(s) */
  /* definition and creation of refersh_lvgl */
  osThreadDef(refersh_lvgl, Refersh_LVGL, osPriorityAboveNormal, 0, 1024);
  refersh_lvglHandle = osThreadCreate(osThread(refersh_lvgl), NULL);

  /* definition and creation of task_FFT */
  osThreadDef(task_FFT, TASK_FFT, osPriorityNormal, 0, 1300);
  task_FFTHandle = osThreadCreate(osThread(task_FFT), NULL);

  /* definition and creation of task_lvgl */
  osThreadDef(task_lvgl, TASK_LVGL, osPriorityNormal, 0, 1300);
  task_lvglHandle = osThreadCreate(osThread(task_lvgl), NULL);

}

void Refersh_LVGL(void const *argument)
{
  /* init code for LWIP */
  MX_LWIP_Init();
  /* USER CODE BEGIN Refersh_LVGL */
  httpd_init();
  FFT_Init(&fft_1V, SAMPLING, FFT_LENGTH, 1); // 1表示电压
  FFT_Init(&fft_2V, SAMPLING, FFT_LENGTH, 1);
  FFT_Init(&fft_3V, SAMPLING, FFT_LENGTH, 1);
  FFT_Init(&fft_NV, SAMPLING, FFT_LENGTH, 1);

  FFT_Init(&fft_1I, SAMPLING, FFT_LENGTH, 0); // 0表示电流
  FFT_Init(&fft_2I, SAMPLING, FFT_LENGTH, 0);
  FFT_Init(&fft_3I, SAMPLING, FFT_LENGTH, 0);
  FFT_Init(&fft_NI, SAMPLING, FFT_LENGTH, 0);

  PHASE_Init(&P1, &fft_1V, &fft_1I);
  PHASE_Init(&P2, &fft_2V, &fft_2I);
  PHASE_Init(&P3, &fft_3V, &fft_3I);
  PHASE_Init(&PN, &fft_NV, &fft_NI);

  Voltage_three_Init(&Voltage, &P1, &P2, &P3);
  /* Infinite loop */
  for (;;)
  {

    // test

    if (lv_disp_get_inactive_time(NULL) < 60000)
    {
      lv_task_handler();
      if(lv_disp_get_inactive_time(NULL) > 30000)
      {
        msg_notice(guider_ui.wave_model_msg, 30000, "30 seconds enters sleep mode");
      }
    }
    /*Sleep after 60 sec inactivity*/
    else
    {
      // // while (!lv_anim_count_running())
      // //   ;
      // 允许外设唤醒系统
      // HAL_SuspendTick(); // 关闭 SysTick 定时器（防止唤醒）

      // GPIO_InitTypeDef GPIO_InitStruct = {0};
      // GPIO_InitStruct.Pin = SKEY_Pin;
      // GPIO_InitStruct.Mode = GPIO_MODE_EVT_FALLING;
      // GPIO_InitStruct.Pull = GPIO_PULLUP;
      // HAL_GPIO_Init(SKEY_GPIO_Port, &GPIO_InitStruct);
      // Display_OFF();
      // // 进入 Stop 模式
      // HAL_PWR_EnterSTOPMode(PWR_MAINREGULATOR_ON, PWR_SLEEPENTRY_WFI);
    }
    osDelay(30);
  }
  /* USER CODE END Refersh_LVGL */
}

void TASK_FFT(void const *argument)
{
  /* USER CODE BEGIN TASK_FFT */
  HAL_NVIC_EnableIRQ(EXTI15_10_IRQn);
  //HAL_TIMEx_PWMN_Start(&htim8, TIM_CHANNEL_3);
  /* Infinite loop */
  for (;;)
  {
    fft_run(&fft_1V);
    fft_run(&fft_2V);
    fft_run(&fft_3V);
    fft_run(&fft_NV);

    fft_run(&fft_1I);
    fft_run(&fft_2I);
    fft_run(&fft_3I);
    fft_run(&fft_NI);

    PHASE_run(&P1);
    PHASE_run(&P2);
    PHASE_run(&P3);
    PHASE_run(&PN);

    Voltage_three_run(&Voltage);
   // HAL_TIMEx_PWMN_Start(&htim8, TIM_CHANNEL_3);
    osDelay(100);
  }
  /* USER CODE END TASK_FFT */
}

void TASK_LVGL(void const *argument)
{
  /* USER CODE BEGIN TASK_LVGL */
  page_init();
  ser1 = lv_chart_add_series(guider_ui.wave_model_chart_2, lv_palette_main(LV_PALETTE_YELLOW), LV_CHART_AXIS_PRIMARY_Y);
  ser2 = lv_chart_add_series(guider_ui.wave_model_chart_2, lv_color_hex(0x00FF00), LV_CHART_AXIS_PRIMARY_Y);
  ser3 = lv_chart_add_series(guider_ui.wave_model_chart_2, lv_palette_main(LV_PALETTE_RED), LV_CHART_AXIS_PRIMARY_Y);
  serN = lv_chart_add_series(guider_ui.wave_model_chart_2, lv_palette_main(LV_PALETTE_BLUE), LV_CHART_AXIS_PRIMARY_Y);
  lv_chart_set_ext_y_array(guider_ui.wave_model_chart_2, ser1, fft_1V.LVGL_wave);
  lv_chart_set_ext_y_array(guider_ui.wave_model_chart_2, ser2, fft_2V.LVGL_wave);
  lv_chart_set_ext_y_array(guider_ui.wave_model_chart_2, ser3, fft_3V.LVGL_wave);
  lv_chart_set_ext_y_array(guider_ui.wave_model_chart_2, serN, fft_NV.LVGL_wave);

  ser1_I = lv_chart_add_series(guider_ui.wave_model_chart_2, lv_palette_main(LV_PALETTE_YELLOW), LV_CHART_AXIS_PRIMARY_Y);
  ser2_I = lv_chart_add_series(guider_ui.wave_model_chart_2, lv_color_hex(0x00FF00), LV_CHART_AXIS_PRIMARY_Y);
  ser3_I = lv_chart_add_series(guider_ui.wave_model_chart_2, lv_palette_main(LV_PALETTE_RED), LV_CHART_AXIS_PRIMARY_Y);
  serN_I = lv_chart_add_series(guider_ui.wave_model_chart_2, lv_palette_main(LV_PALETTE_BLUE), LV_CHART_AXIS_PRIMARY_Y);
  ser1_I->hidden = 1;
  ser2_I->hidden = 1;
  ser3_I->hidden = 1;
  serN_I->hidden = 1;
  lv_chart_set_ext_y_array(guider_ui.wave_model_chart_2, ser1_I, fft_1I.LVGL_wave);
  lv_chart_set_ext_y_array(guider_ui.wave_model_chart_2, ser2_I, fft_2I.LVGL_wave);
  lv_chart_set_ext_y_array(guider_ui.wave_model_chart_2, ser3_I, fft_3I.LVGL_wave);
  lv_chart_set_ext_y_array(guider_ui.wave_model_chart_2, serN_I, fft_NI.LVGL_wave);

  lv_chart_series_t *ser_xb_1 = lv_chart_add_series(guider_ui.wave_model_chart_3, lv_palette_main(LV_PALETTE_YELLOW), LV_CHART_AXIS_PRIMARY_Y);
  lv_chart_series_t *ser_xb_2 = lv_chart_add_series(guider_ui.wave_model_chart_3, lv_color_hex(0x00FF00), LV_CHART_AXIS_PRIMARY_Y);
  lv_chart_series_t *ser_xb_3 = lv_chart_add_series(guider_ui.wave_model_chart_3, lv_palette_main(LV_PALETTE_RED), LV_CHART_AXIS_PRIMARY_Y);
  lv_chart_set_ext_y_array(guider_ui.wave_model_chart_3, ser_xb_1, fft_1V.LVGL_xb);
  lv_chart_set_ext_y_array(guider_ui.wave_model_chart_3, ser_xb_2, fft_2V.LVGL_xb);
  lv_chart_set_ext_y_array(guider_ui.wave_model_chart_3, ser_xb_3, fft_3V.LVGL_xb);
  /* Infinite loop */
  for (;;)
  {
    task_page();
    osDelay(1000);
  }
  /* USER CODE END TASK_LVGL */
}

/* USER CODE BEGIN Application */
/**
 * @brief  EXTI line detection callback.
 * @param  GPIO_Pin: Specifies the port pin connected to corresponding EXTI line.
 * @retval None
 */
/* NOTE::::::::::::::::::::::::::::::::::::::::::::::::::::::::::::::::::::::::::
              __HAL_GPIO_EXTI_CLEAR_IT(GPIO_Pin);
This function Should not be modified in the hal_gpio file, when the callback is needed,
           the HAL_GPIO_EXTI_Callback could be implemented in the user file
::::::::::::::::::::::::::::::::::::::::::::::::::::::::::::::::::::::::::::::::*/
void HAL_GPIO_EXTI_Callback(uint16_t GPIO_Pin)
{
  // GPIO_PIN_12 == ADC Complete interrupt
  if (GPIO_Pin == GPIO_PIN_12)
  {
    Get_AD7606();
  }
  if (GPIO_Pin == SKEY_Pin)
  {
    // 重新初始化外设
    init_form_stop();
  }
}
void init_form_stop()
{
  // 1. 重新配置时钟
  SystemClock_Config();

  // 2. 恢复 tick
  HAL_ResumeTick();

  // 3. 重新初始化需要的外设
  MX_USART1_UART_Init();
  MX_USART3_UART_Init();
  MX_UART4_Init();

  MX_SPI1_Init();
  MX_SPI3_Init();
  MX_SPI4_Init();

  MX_I2C1_Init();
  MX_I2C4_Init();

  MX_SDMMC1_SD_Init();
  MX_USB_OTG_FS_PCD_Init();
  MX_QUADSPI_Init();

  // 若用 ADC / 定时器：
  MX_ADC1_Init();
  MX_TIM1_Init();
  MX_TIM3_Init();
  MX_TIM8_Init();

  SystemClock_Config();
  HAL_ResumeTick();

  MX_FATFS_Init();
  lv_port_fs_init();
  lv_port_disp_init();
  lv_port_indev_init();

  HAL_SD_MspInit(&hsd1);
  HAL_TIM_Base_Start_IT(&htim1);
  ad7606ini(&ad7606dev);
  FatFs_Check();
  Display_Text(250, 230, 1, "WAKE UP");
  Display_ON();
  HAL_Delay(5000);
}

/* USER CODE END Application */

/************************ (C) COPYRIGHT STMicroelectronics *****END OF FILE****/
